# DMASS_INTAGGR_0_INTAGGR_CFG_48110000h register map
Vendor: Texas Instruments
Peripheral module from a debugger description file (folder AM275x).
Registers are 64-bit, read-only, reset 0x66961101 unless marked. A register's access mark holds for its fields unless they carry their own. Offsets are as the file gives them; lines under a group give offsets from that group; [hi:lo] are bit positions; {n}, {i} and the like mark numbered series; 'fields as' and 'values as' point back to an identical list; <NAME> marks a mode.

## intaggr_cfg
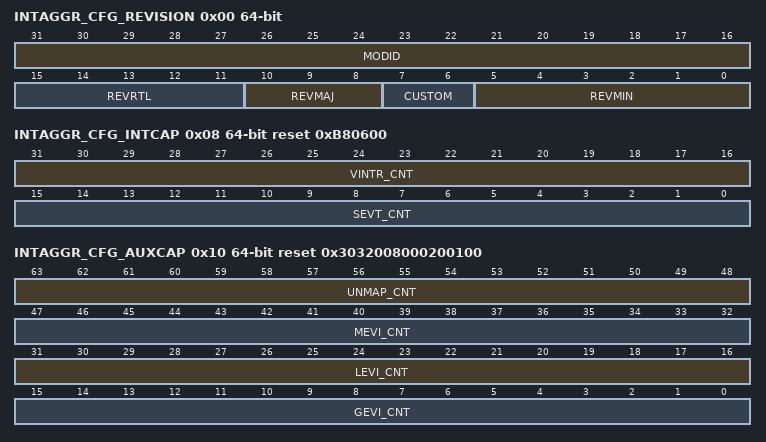
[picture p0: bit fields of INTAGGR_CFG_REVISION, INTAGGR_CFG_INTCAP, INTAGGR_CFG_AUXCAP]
0x00 INTAGGR_CFG_REVISION — The Revision Register contains the major and minor revisions for the module.
  [31:16] MODID — Module ID field Reset Source: srst_n
  [15:11] REVRTL — RTL revision. Will vary depending on release. Reset Source: srst_n
  [10:8] REVMAJ — Major revision Reset Source: srst_n
  [7:6] CUSTOM — Custom Reset Source: srst_n
  [5:0] REVMIN — Minor revision Reset Source: srst_n
0x08 INTAGGR_CFG_INTCAP reset 0xB80600 — The IntCap Register contains information on virtual interrupts.
  [31:16] VINTR_CNT — Virtual interrupt register/pin count Reset Source: srst_n
  [15:0] SEVT_CNT — Number of 'event to virt int' mapping registers Reset Source: srst_n
0x10 INTAGGR_CFG_AUXCAP reset 0x3032008000200100 — The AuxCap Register contains information on additional capabilities.
  [63:48] UNMAP_CNT — Number of multicast event registers. Not all registers in the range are necessarily valid. Reset Source: srst_n
  [47:32] MEVI_CNT — Number of multicast event registers Reset Source: srst_n
  [31:16] LEVI_CNT — Local input events for local to global translation Reset Source: srst_n
  [15:0] GEVI_CNT — Number of event counting registers Reset Source: srst_n
